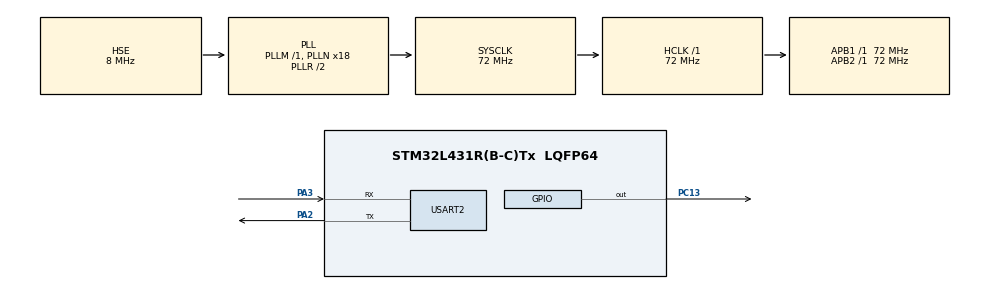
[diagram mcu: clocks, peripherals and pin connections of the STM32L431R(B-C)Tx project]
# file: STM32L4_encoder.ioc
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FREERTOS.Tasks01=led_task,24,128,LED_TASK,Default,NULL,Dynamic,NULL,NULL;elogTask,24,128,ThreadElog,Default,NULL,Dynamic,NULL,NULL
FREERTOS.configUSE_NEWLIB_REENTRANT=0
Mcu.Family=STM32L4
Mcu.Name=STM32L431R(B-C)Tx
Mcu.Package=LQFP64
NVIC.PriorityGroup=NVIC_PRIORITYGROUP_4
NVIC.TIM1_UP_TIM16_IRQn=true\:0\:0\:true\:false\:true\:false\:false\:true\:true
NVIC.TimeBase=TIM1_UP_TIM16_IRQn
NVIC.TimeBaseIP=TIM16
PA13\ (JTMS-SWDIO).Mode=Serial_Wire
PA13\ (JTMS-SWDIO).Signal=SYS_JTMS-SWDIO
PA14\ (JTCK-SWCLK).Mode=Serial_Wire
PA14\ (JTCK-SWCLK).Signal=SYS_JTCK-SWCLK
PA2.Mode=Asynchronous
PA2.Signal=USART2_TX
PA3.Mode=Asynchronous
PA3.Signal=USART2_RX
PC13.Signal=GPIO_Output
PH0-OSC_IN\ (PH0).Mode=HSE-External-Oscillator
PH0-OSC_IN\ (PH0).Signal=RCC_OSC_IN
PH1-OSC_OUT\ (PH1).Mode=HSE-External-Oscillator
PH1-OSC_OUT\ (PH1).Signal=RCC_OSC_OUT
ProjectManager.HeapSize=0x200
ProjectManager.StackSize=0x400
ProjectManager.TargetToolchain=STM32CubeIDE
RCC.ADCFreq_Value=32000000
RCC.AHBFreq_Value=72000000
RCC.APB1Freq_Value=72000000
RCC.APB1TimFreq_Value=72000000
RCC.APB2Freq_Value=72000000
RCC.APB2TimFreq_Value=72000000
RCC.CortexFreq_Value=72000000
RCC.HCLKFreq_Value=72000000
RCC.HSE_VALUE=8000000
RCC.HSI48_VALUE=48000000
RCC.HSI_VALUE=16000000
RCC.LSE_VALUE=32768
RCC.MSI_VALUE=4000000
RCC.PLLN=18
RCC.PLLSourceVirtual=RCC_PLLSOURCE_HSE
RCC.SYSCLKFreq_VALUE=72000000
RCC.SYSCLKSource=RCC_SYSCLKSOURCE_PLLCLK
RCC.VCOOutputFreq_Value=144000000
USART2.VirtualMode-Asynchronous=VM_ASYNC
VP_FREERTOS_VS_CMSIS_V2.Mode=CMSIS_V2
VP_SYS_VS_tim16.Mode=TIM16
board=custom

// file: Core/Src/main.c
/* USER CODE BEGIN Header */
/**
  ******************************************************************************
  * @file           : main.c
  * @brief          : Main program body
  ******************************************************************************
  * @attention
  *
  * Copyright (c) 2023 STMicroelectronics.
  * All rights reserved.
  *
  * This software is licensed under terms that can be found in the LICENSE file
  * in the root directory of this software component.
  * If no LICENSE file comes with this software, it is provided AS-IS.
  *
  ******************************************************************************
  */
/* USER CODE END Header */
#include "main.h"
#include "cmsis_os.h"
#include "usart.h"
#include "gpio.h"

/* USER CODE BEGIN Includes */
#include "elog.h"
/* USER CODE END Includes */

void SystemClock_Config(void);
void MX_FREERTOS_Init(void);

/* USER CODE BEGIN 0 */
void agi_log_init(void);
/* USER CODE END 0 */

int main(void)
{

  /* MCU Configuration--------------------------------------------------------*/

  /* Reset of all peripherals, Initializes the Flash interface and the Systick. */
  HAL_Init();

  /* Configure the system clock */
  SystemClock_Config();

  /* Initialize all configured peripherals */
  MX_GPIO_Init();
  MX_USART2_UART_Init();
  /* USER CODE BEGIN 2 */
    agi_log_init();
  /* USER CODE END 2 */

  /* Init scheduler */
  osKernelInitialize();  /* Call init function for freertos objects (in freertos.c) */
  MX_FREERTOS_Init();

  /* Start scheduler */
  osKernelStart();

  /* We should never get here as control is now taken by the scheduler */
  /* Infinite loop */
    while (1)
    {

    }
}

void SystemClock_Config(void)
{
  RCC_OscInitTypeDef RCC_OscInitStruct = {0};
  RCC_ClkInitTypeDef RCC_ClkInitStruct = {0};

  /** Configure the main internal regulator output voltage
  */
  if (HAL_PWREx_ControlVoltageScaling(PWR_REGULATOR_VOLTAGE_SCALE1) != HAL_OK)
  {
    Error_Handler();
  }

  /** Initializes the RCC Oscillators according to the specified parameters
  * in the RCC_OscInitTypeDef structure.
  */
  RCC_OscInitStruct.OscillatorType = RCC_OSCILLATORTYPE_HSE;
  RCC_OscInitStruct.HSEState = RCC_HSE_ON;
  RCC_OscInitStruct.PLL.PLLState = RCC_PLL_ON;
  RCC_OscInitStruct.PLL.PLLSource = RCC_PLLSOURCE_HSE;
  RCC_OscInitStruct.PLL.PLLM = 1;
  RCC_OscInitStruct.PLL.PLLN = 18;
  RCC_OscInitStruct.PLL.PLLP = RCC_PLLP_DIV7;
  RCC_OscInitStruct.PLL.PLLQ = RCC_PLLQ_DIV2;
  RCC_OscInitStruct.PLL.PLLR = RCC_PLLR_DIV2;
  if (HAL_RCC_OscConfig(&RCC_OscInitStruct) != HAL_OK)
  {
    Error_Handler();
  }

  /** Initializes the CPU, AHB and APB buses clocks
  */
  RCC_ClkInitStruct.ClockType = RCC_CLOCKTYPE_HCLK|RCC_CLOCKTYPE_SYSCLK
                              |RCC_CLOCKTYPE_PCLK1|RCC_CLOCKTYPE_PCLK2;
  RCC_ClkInitStruct.SYSCLKSource = RCC_SYSCLKSOURCE_PLLCLK;
  RCC_ClkInitStruct.AHBCLKDivider = RCC_SYSCLK_DIV1;
  RCC_ClkInitStruct.APB1CLKDivider = RCC_HCLK_DIV1;
  RCC_ClkInitStruct.APB2CLKDivider = RCC_HCLK_DIV1;

  if (HAL_RCC_ClockConfig(&RCC_ClkInitStruct, FLASH_LATENCY_4) != HAL_OK)
  {
    Error_Handler();
  }
}

/* USER CODE BEGIN 4 */
void OnTimerCallback(TIM_TypeDef *timInstance);
void agi_log_init(void)
{
    elog_init();
    /* set EasyLogger log format */
    elog_set_fmt(ELOG_LVL_ASSERT, ELOG_FMT_ALL);
    elog_set_fmt(ELOG_LVL_ERROR, ELOG_FMT_LVL | ELOG_FMT_TAG | ELOG_FMT_TIME);
    elog_set_fmt(ELOG_LVL_WARN, ELOG_FMT_LVL | ELOG_FMT_TAG | ELOG_FMT_TIME);
    elog_set_fmt(ELOG_LVL_INFO, ELOG_FMT_LVL | ELOG_FMT_TAG | ELOG_FMT_TIME);
    elog_set_fmt(ELOG_LVL_DEBUG, ELOG_FMT_ALL & ~(ELOG_FMT_FUNC | ELOG_FMT_T_INFO | ELOG_FMT_P_INFO));
    elog_set_fmt(ELOG_LVL_VERBOSE, ELOG_FMT_ALL & ~(ELOG_FMT_FUNC | ELOG_FMT_T_INFO | ELOG_FMT_P_INFO));
    /* start EasyLogger */
    elog_start();
}
/* USER CODE END 4 */

void HAL_TIM_PeriodElapsedCallback(TIM_HandleTypeDef *htim)
{
  if (htim->Instance == TIM16) {
    HAL_IncTick();
  }
}

void Error_Handler(void)
{
    __disable_irq();
    while (1)
    {
    }
}

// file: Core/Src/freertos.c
/* USER CODE BEGIN Header */
/**
  ******************************************************************************
  * File Name          : freertos.c
  * Description        : Code for freertos applications
  ******************************************************************************
  * @attention
  *
  * Copyright (c) 2023 STMicroelectronics.
  * All rights reserved.
  *
  * This software is licensed under terms that can be found in the LICENSE file
  * in the root directory of this software component.
  * If no LICENSE file comes with this software, it is provided AS-IS.
  *
  ******************************************************************************
  */
/* USER CODE END Header */

#include "FreeRTOS.h"
#include "task.h"
#include "main.h"
#include "cmsis_os.h"

/* USER CODE BEGIN Includes */
#include "common_inc.h"
#include "my_task.h"
/* USER CODE END Includes */

/* USER CODE BEGIN PM */
osSemaphoreId elog_lockHandle;
osSemaphoreId elog_asyncHandle;
osThreadId_t easylogTaskHandle;
/* USER CODE END PM */

/* Definitions for led_task */
osThreadId_t led_taskHandle;
const osThreadAttr_t led_task_attributes = {
  .name = "led_task",
  .stack_size = 128 * 4,
  .priority = (osPriority_t) osPriorityNormal,
};
/* Definitions for elogTask */
osThreadId_t elogTaskHandle;
const osThreadAttr_t elogTask_attributes = {
  .name = "elogTask",
  .stack_size = 128 * 4,
  .priority = (osPriority_t) osPriorityNormal,
};

void LED_TASK(void *argument);
void ThreadElog(void *argument);

void MX_FREERTOS_Init(void); /* (MISRA C 2004 rule 8.1) */

void MX_FREERTOS_Init(void) {

  /* USER CODE BEGIN RTOS_SEMAPHORES */
    /* add semaphores, ... */
    osSemaphoreDef(elog_lockHandle);
    elog_lockHandle = osSemaphoreNew(1, 1, osSemaphore(elog_lockHandle));

    osSemaphoreDef(elog_asyncHandle);
    elog_asyncHandle = osSemaphoreNew(1, 1, osSemaphore(elog_asyncHandle));
  /* USER CODE END RTOS_SEMAPHORES */

  /* Create the thread(s) */
  /* creation of led_task */
  led_taskHandle = osThreadNew(LED_TASK, NULL, &led_task_attributes);

  /* creation of elogTask */
  elogTaskHandle = osThreadNew(ThreadElog, NULL, &elogTask_attributes);

}

void LED_TASK(void *argument)
{
  /* USER CODE BEGIN LED_TASK */
    log_i ("hello! you can use elog!");
    /* Infinite loop */
    for(;;)
    {
        my_task();
    }
  /* USER CODE END LED_TASK */
}

//void ThreadElog(void *argument)
//{
//  /* USER CODE BEGIN ThreadElog */
//////////  /* Infinite loop */
//////////  for(;;)
//////////  {
//////////    osDelay(1);
//////////  }
//  /* USER CODE END ThreadElog */
//}
